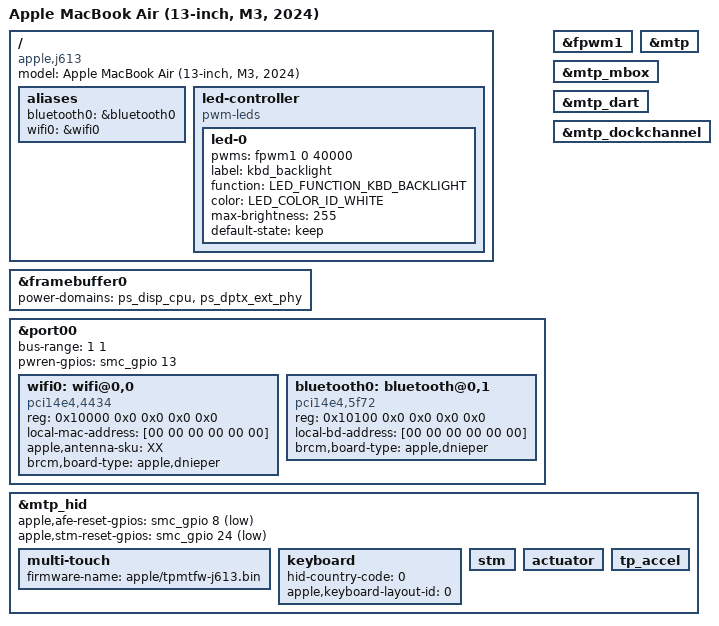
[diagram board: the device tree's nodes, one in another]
// SPDX-License-Identifier: GPL-2.0+ OR MIT
/*
 * Apple MacBook Air (13-inch, M3, 2024)
 *
 * target-type: J613
 *
 * Copyright The Asahi Linux Contributors
 */

/dts-v1/;

#include "t8122.dtsi"
#include "t8122-jxxx.dtsi"
#include <dt-bindings/leds/common.h>

/ {
	compatible = "apple,j613", "apple,t8122", "apple,arm-platform";
	model = "Apple MacBook Air (13-inch, M3, 2024)";

	aliases {
		bluetooth0 = &bluetooth0;
		wifi0 = &wifi0;
	};

	led-controller {
		compatible = "pwm-leds";
		led-0 {
			pwms = <&fpwm1 0 40000>;
			label = "kbd_backlight";
			function = LED_FUNCTION_KBD_BACKLIGHT;
			color = <LED_COLOR_ID_WHITE>;
			max-brightness = <255>;
			default-state = "keep";
		};
	};
};

&framebuffer0 {
	// panel = &panel;
	power-domains = <&ps_disp_cpu>, <&ps_dptx_ext_phy>;
};

/*
 * Force the bus number assignments so that we can declare some of the
 * on-board devices and properties that are populated by the bootloader
 * (such as MAC addresses).
 */
&port00 {
	bus-range = <1 1>;
	pwren-gpios = <&smc_gpio 13 GPIO_ACTIVE_HIGH>;
	wifi0: wifi@0,0 {
		compatible = "pci14e4,4434";
		reg = <0x10000 0x0 0x0 0x0 0x0>;
		/* To be filled by the loader */
		local-mac-address = [00 00 00 00 00 00];
		apple,antenna-sku = "XX";
		brcm,board-type = "apple,dnieper";
	};

	bluetooth0: bluetooth@0,1 {
		compatible = "pci14e4,5f72";
		reg = <0x10100 0x0 0x0 0x0 0x0>;
		/* To be filled by the loader */
		local-bd-address = [00 00 00 00 00 00];
		brcm,board-type = "apple,dnieper";
	};
};

&fpwm1 {
	status = "okay";
};

&mtp {
	status = "okay";
};

&mtp_mbox {
	status = "okay";
};

&mtp_dart {
	status = "okay";
};

&mtp_dockchannel {
	status = "okay";
};

&mtp_hid {
	apple,afe-reset-gpios = <&smc_gpio 8 GPIO_ACTIVE_LOW>;
	apple,stm-reset-gpios = <&smc_gpio 24 GPIO_ACTIVE_LOW>;

	multi-touch {
	 	firmware-name = "apple/tpmtfw-j613.bin";
	};

	keyboard: keyboard {
		hid-country-code = <0>;
		apple,keyboard-layout-id = <0>;
	};

	stm {
	};

	actuator {
	};

	tp_accel {
	};
};
